# A31T21x register map
Vendor: ABOV Semiconductor Co., Ltd.; Series: A31T21x; File version: 1.0
CPU: CM0PLUS r0p1, little endian, no MPU, no FPU, VTOR, 2 interrupt priority bits
Registers are 32-bit, read-write, reset 0x0 unless marked. A register's access mark holds for its fields unless they carry their own. Offsets are from the block's base; [hi:lo] are bit positions; {n}, {i} and the like mark numbered series.

## SCU — System Control Unit
Base 0x40000000
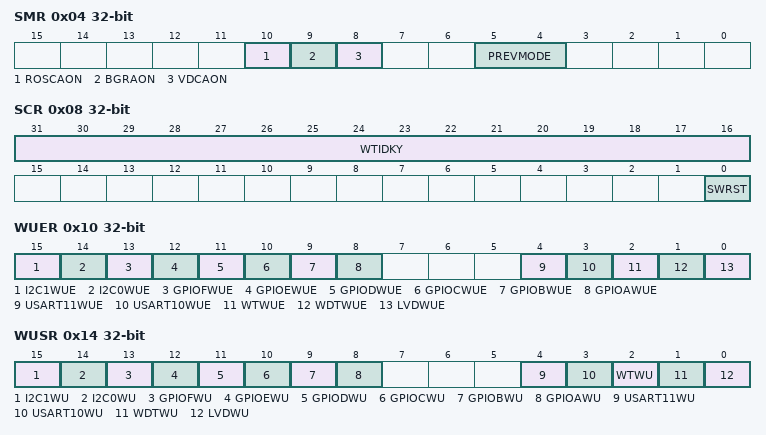
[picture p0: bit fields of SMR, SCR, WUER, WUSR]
0x04 SMR — System Mode Register
  [10] ROSCAON — ROSC Always on select bit in power down mode 0: ROSC is automatically off entering power down mode 1: ROSC isn't automatically off entering power down mode
  [9] BGRAON — BGR Always on select bit in power down mode 0: BGR is automatically off entering power down mode 1: BGR isn't automatically off entering power down mode
  [8] VDCAON — VDC Always on select bit in power down mode
  [5:4] PREVMODE ro — Previous operating mode before current reset event
0x08 SCR — System Control Register
  [31:16] WTIDKY wo — On writes, write 0x9EB3 to these bits, otherwise the write is ignored.
  [0] SWRST — Internal soft reset activation bit (check RSER[4] for reset)
0x10 WUER — Wake up source enable register
  [15] I2C1WUE — Enable wakeup source of I2C1 event
  [14] I2C0WUE — Enable wakeup source of I2C0 event
  [13] GPIOFWUE — Enable wakeup source of GPIOF port pin change event
  [12] GPIOEWUE — Enable wakeup source of GPIOE port pin change event
  [11] GPIODWUE — Enable wakeup source of GPIOD port pin change event
  [10] GPIOCWUE — Enable wakeup source of GPIOC port pin change event
  [9] GPIOBWUE — Enable wakeup source of GPIOB port pin change event
  [8] GPIOAWUE — Enable wakeup source of GPIOA port pin change event
  [4] USART11WUE — Enable wakeup source of USART11 event
  [3] USART10WUE — Enable wakeup source of USART10 event
  [2] WTWUE — Enable wakeup source of watch timer event
  [1] WDTWUE — Enable wakeup source of watchdog timer event
  [0] LVDWUE — Enable wakeup source of LVD event
0x14 WUSR ro — Wake up source status register
  [15] I2C1WU — Status of wakeup source of I2C1 event
  [14] I2C0WU — Status of wakeup source of I2C0 event
  [13] GPIOFWU — Status of wakeup source of GPIOF port pin change event
  [12] GPIOEWU — Status of wakeup source of GPIOE port pin change event
  [11] GPIODWU — Status of wakeup source of GPIOD port pin change event
  [10] GPIOCWU — Status of wakeup source of GPIOC port pin change event
  [9] GPIOBWU — Status of wakeup source of GPIOB port pin change event
  [8] GPIOAWU — Status of wakeup source of GPIOA port pin change event
  [4] USART11WU — Status of wakeup source of USART11 event
  [3] USART10WU — Status of wakeup source of USART10 event
  [2] WTWU — Status of wakeup source of watch timer event
  [1] WDTWU — Status of wakeup source of watchdog timer event
  [0] LVDWU — Status of wakeup source of LVD event
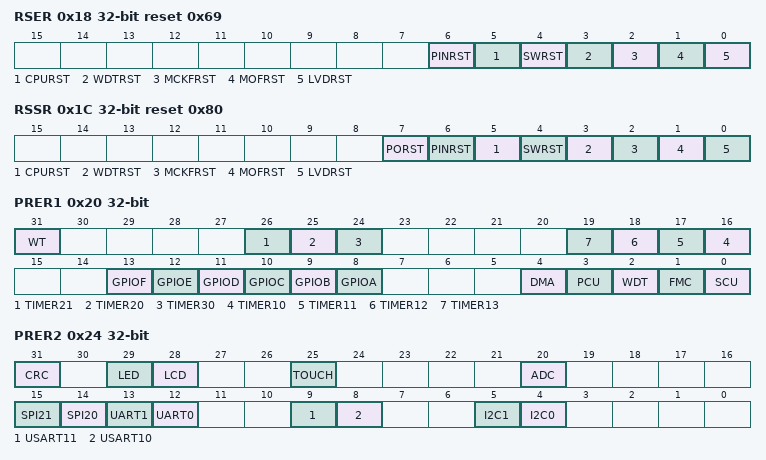
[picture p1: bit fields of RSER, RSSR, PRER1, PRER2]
0x18 RSER reset 0x69 — Reset source enable register
  [6] PINRST — External pin reset enable bit
  [5] CPURST — CPU request reset enable bit
  [4] SWRST — Software reset enable bit
  [3] WDTRST — Watchdog Timer reset enable bit
  [2] MCKFRST — MCLK Clock fail reset enable bit
  [1] MOFRST — MOSC Clock fail reset enable bit
  [0] LVDRST — LVD reset enable bit
0x1C RSSR reset 0x80 — Reset source status register
  [7] PORST — Power on reset status bit
  [6] PINRST — External pin reset status bit
  [5] CPURST — CPU request reset status bit
  [4] SWRST — Software reset status bit
  [3] WDTRST — Watchdog Timer reset status bit
  [2] MCKFRST — MCLK Clock fail reset status bit
  [1] MOFRST — MOSC Clock fail reset status bit
  [0] LVDRST — LVD reset status bit
0x20 PRER1 — Peripheral reset enable register 1
  [31] WT — WT reset mask
  [26] TIMER21 — TIMER21 reset mask
  [25] TIMER20 — TIMER20 reset mask
  [24] TIMER30 — TIMER30 reset mask
  [n+6] TIMER{n} (n=10..13) — TIMER{n} reset mask
  [13] GPIOF — GPIOF reset mask
  [12] GPIOE — GPIOE reset mask
  [11] GPIOD — GPIOD reset mask
  [10] GPIOC — GPIOC reset mask
  [9] GPIOB — GPIOB reset mask
  [8] GPIOA — GPIOA reset mask
  [4] DMA — DMA reset mask
  [3] PCU — PCU reset mask
  [2] WDT — WDT reset mask
  [1] FMC — FMC reset mask
  [0] SCU — SCU reset mask
0x24 PRER2 — Peripheral reset enable register 2
  [31] CRC — CRC reset mask
  [29] LED — LED reset mask
  [28] LCD — LCD reset mask
  [25] TOUCH — TOUCH reset mask
  [20] ADC — ADC reset mask
  [15] SPI21 — SPI21 reset mask
  [14] SPI20 — SPI20 reset mask
  [13] UART1 — UART1 reset mask
  [12] UART0 — UART0 reset mask
  [9] USART11 — USART11 reset mask
  [8] USART10 — USART10 reset mask
  [5] I2C1 — I2C1 reset mask
  [4] I2C0 — I2C0 reset mask
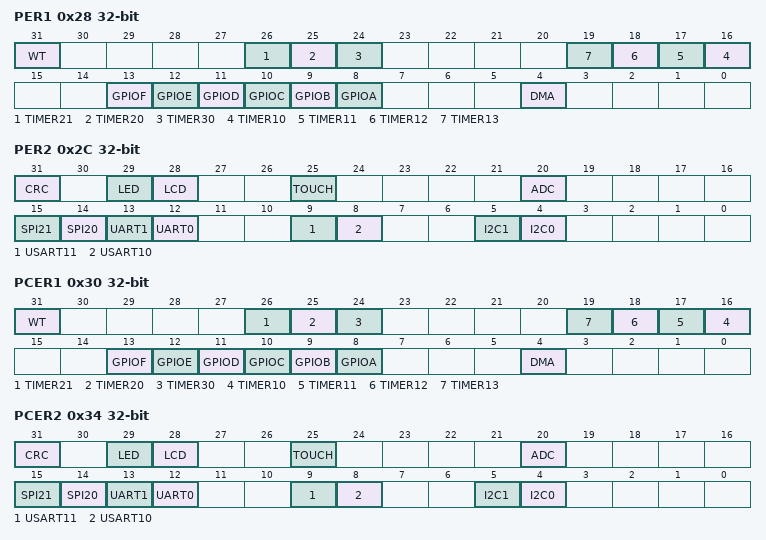
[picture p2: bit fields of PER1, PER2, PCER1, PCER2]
0x28 PER1 — Peripheral enable register 1
  [31] WT — WT function enable
  [26] TIMER21 — TIMER21 function enable
  [25] TIMER20 — TIMER20 function enable
  [24] TIMER30 — TIMER30 function enable
  [n+6] TIMER{n} (n=10..13) — TIMER{n} function enable
  [13] GPIOF — GPIOF function enable
  [12] GPIOE — GPIOE function enable
  [11] GPIOD — GPIOD function enable
  [10] GPIOC — GPIOC function enable
  [9] GPIOB — GPIOB function enable
  [8] GPIOA — GPIOA function enable
  [4] DMA — DMA function enable
0x2C PER2 — Peripheral enable register 2
  [31] CRC — CRC function enable
  [29] LED — LED function enable
  [28] LCD — LCD function enable
  [25] TOUCH — TOUCH function enable
  [20] ADC — ADC function enable
  [15] SPI21 — SPI21 function enable
  [14] SPI20 — SPI20 function enable
  [13] UART1 — UART1 function enable
  [12] UART0 — UART0 function enable
  [9] USART11 — USART11 function enable
  [8] USART10 — USART10 function enable
  [5] I2C1 — I2C1 function enable
  [4] I2C0 — I2C0 function enable
0x30 PCER1 — Peripheral clock enable register 1
  [31] WT — WT clock enable
  [26] TIMER21 — TIMER21 clock enable
  [25] TIMER20 — TIMER20 clock enable
  [24] TIMER30 — TIMER30 clock enable
  [n+6] TIMER{n} (n=10..13) — TIMER{n} clock enable
  [13] GPIOF — GPIOF clock enable
  [12] GPIOE — GPIOE clock enable
  [11] GPIOD — GPIOD clock enable
  [10] GPIOC — GPIOC clock enable
  [9] GPIOB — GPIOB clock enable
  [8] GPIOA — GPIOA clock enable
  [4] DMA — DMA clock enable
0x34 PCER2 — Peripheral clock enable register 2
  [31] CRC — CRC clock enable
  [29] LED — LED clock enable
  [28] LCD — LCD clock enable
  [25] TOUCH — TOUCH clock enable
  [20] ADC — ADC clock enable
  [15] SPI21 — SPI21 clock enable
  [14] SPI20 — SPI20 clock enable
  [13] UART1 — UART1 clock enable
  [12] UART0 — UART0 clock enable
  [9] USART11 — USART11 clock enable
  [8] USART10 — USART10 clock enable
  [5] I2C1 — I2C1 clock enable
  [4] I2C0 — I2C0 clock enable
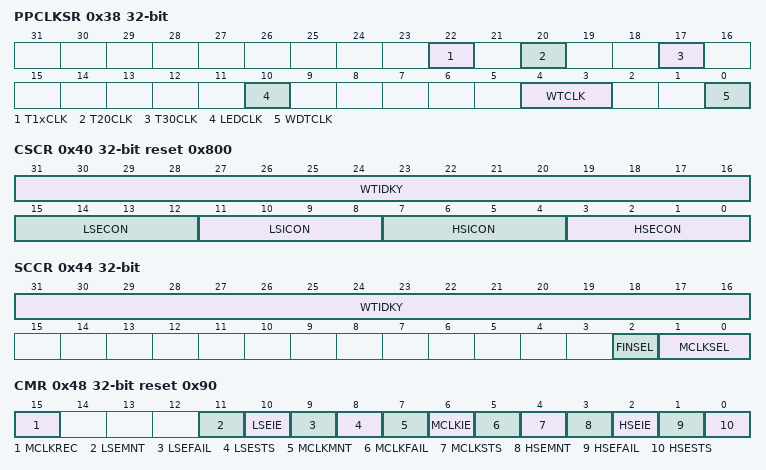
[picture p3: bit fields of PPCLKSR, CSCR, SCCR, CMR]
0x38 PPCLKSR — Peripheral clock selection register
  [22] T1xCLK — Timer 1x Clock Selection bit
  [20] T20CLK — Timer 20 Clock Selection bit
  [17] T30CLK — Timer 30 Clock Selection bit
  [10] LEDCLK — LED Clock Selection bit
  [4:3] WTCLK — Watch Timer Clock Selection bit Note) These bits should be changed during the WTEN bit of watch timer control register (WTCR) is "0b"
  [0] WDTCLK — Watch-dog Timer Clock Selection bit
0x40 CSCR reset 0x800 — Clock Source Control register
  [31:16] WTIDKY wo — On writes, write 0xA507 to these bits, otherwise the write is ignored.
  [15:12] LSECON — External crystal sub oscillator control
  [11:8] LSICON — Low speed internal oscillator control
  [7:4] HSICON — High speed internal oscillator control
  [3:0] HSECON — External crystal main oscillator control
0x44 SCCR — System Clock Control register
  [31:16] WTIDKY wo — On writes, write 0x570A to these bits, otherwise the write is ignored.
  [2] FINSEL — PLL input source FIN select register
  [1:0] MCLKSEL — System clock select register
0x48 CMR reset 0x90 — Clock Monitoring register
  [15] MCLKREC — MCLK fail auto recovery
  [11] LSEMNT — External sub oscillator monitoring enable
  [10] LSEIE — External sub oscillator fail interrupt enable
  [9] LSEFAIL — External sub oscillator fail interrupt
  [8] LSESTS — External sub oscillator status
  [7] MCLKMNT — MCLK monitoring enable
  [6] MCLKIE — MCLK fail interrupt enable
  [5] MCLKFAIL — MCLK fail interrupt
  [4] MCLKSTS — MCLK clock status
  [3] HSEMNT — External main oscillator monitoring enable
  [2] HSEIE — External main oscillator fail interrupt enable
  [1] HSEFAIL — External main oscillator fail interrupt
  [0] HSESTS — External main oscillator status
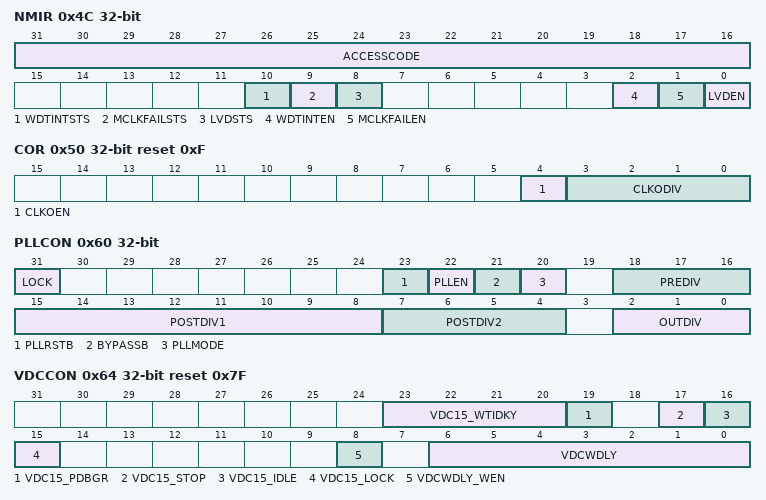
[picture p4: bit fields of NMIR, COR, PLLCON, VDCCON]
0x4C NMIR — NMI control register
  [31:16] ACCESSCODE wo — This field enables writing access to this register. Writing 0xA32C is to enable writing.
  [10] WDTINTSTS ro — WDT Interrupt condition status bit This bit can't invoke NMI interrupt without enable bit
  [9] MCLKFAILSTS ro — MCLK Fail condition status bit This bit can't invoke NMI interrupt without enable bit
  [8] LVDSTS ro — LVD condition status bit This bit can't invoke NMI interrupt without enable bit
  [2] WDTINTEN — WDT Interrupt condition enable for NMI interrupt
  [1] MCLKFAILEN — MCLK Fail condition enable for NMI interrupt
  [0] LVDEN — LVD Fail condition enable for NMI interrupt
0x50 COR reset 0xF — Clock Output Control register
  [4] CLKOEN — Clock output enable
  [3:0] CLKODIV — Clock output divider value CLKO=MCLK (CLKODIV=0) CLKO=MCLK/2(CLKODIV+1) (CLKODIV > 0)
0x60 PLLCON — PLL Control register
  [31] LOCK ro — LOCK status
  [23] PLLRSTB — PLL reset
  [22] PLLEN — PLL enable
  [21] BYPASSB — FIN bypass
  [20] PLLMODE — PLL VCO mode
  [18:16] PREDIV — FIN predivider FIN divided by (PREDIV + 1), (FIN/1 ~ FIN/8)
  [15:8] POSTDIV1 — Feedback control 1 (N1) N1 = POSTDIV1 + 1
  [7:4] POSTDIV2 — Feedback control 1 (N2) N2 = POSTDIV2 + 1
  [2:0] OUTDIV — output divider control (P) P = OUTDIV + 1
0x64 VDCCON reset 0x7F — VDC Control register
  [23:20] VDC15_WTIDKY wo — VDC15 Write Identification Key On writes, write 0x5 to these bits, otherwise the write is ignored.
  [19] VDC15_PDBGR — VDC15 1.2V BGR / 1.0V Buffer Power Down Signal *In BGR on off, VDCLOCK_I should be 0
  [17] VDC15_STOP — VDC15 STOP Mode Control Signal
  [16] VDC15_IDLE — VDC15 STOP1 Mode Control Signal
  [15] VDC15_LOCK — VDC15 VDCLOCK Control Signal for *BGR Stabilization *In BGR off on Sequence, VDCLOCK_I should be 0 during 120usec
  [8] VDCWDLY_WEN wo — VDCWDLY value write enable. VDCWDLY value can be written with writing '1' to VDCWDLY_WEN bit simultaneously.
  [6:0] VDCWDLY — VDC warm-up delay count value. When SCU is waked up from powerdown mode, the warm-up delay is inserted for VDC output being stabilized. The amount of delay can be defined with this register value 7F : 4msec
0x68 TIRCCON — On chip Internal IRC for Touch control register
  [0] TIRCON — Touch IRC Control signal
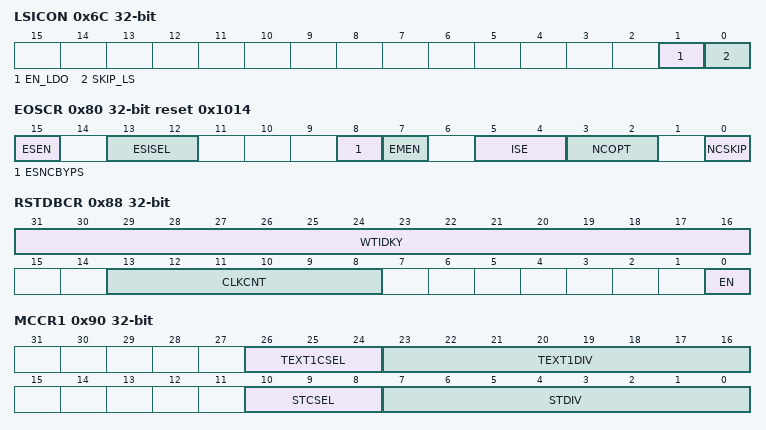
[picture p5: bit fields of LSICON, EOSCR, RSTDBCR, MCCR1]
0x6C LSICON — LSI Control Register
  [1] EN_LDO — Internal LDO On/Off
  [0] SKIP_LS — Internal Level Shifter control signal
0x80 EOSCR reset 0x1014 — External Oscillator control register
  [15] ESEN wo — Write enable for External SOSC
  [13:12] ESISEL — Internal Level Shifter control signal
  [8] ESNCBYPS — Noise Cancel Bypass enable for External SOSC
  [7] EMEN wo — Write enable for External MOSC
  [5:4] ISE — Select current for External MOSC
  [3:2] NCOPT — Noise Cancel delay Option for External MOSC
  [0] NCSKIP — Noise Cancel Bypass enable for External SOSC
0x84 EMODR — External mode pin read register
  [0] BOOT ro — BOOT pin level
0x88 RSTDBCR — Pin Reset Debounce Control Register
  [31:16] WTIDKY wo — Write Identification Key
  [13:8] CLKCNT — Noise Cancel delay Option for External HSE
  [0] EN — Pin reset debounce enable bit
0x90 MCCR1 — Miscellaneous Clock Control Register 1
  [26:24] TEXT1CSEL — TIMER1n EXT Clock source select bit
  [23:16] TEXT1DIV — TIMER1n EXT Clock N divider To change the value, set 0x0 first without changing TEXT1CSEL
  [10:8] STCSEL — systick clock source sel
  [7:0] STDIV — SYSTICK Clock N divider To change the value, set 0x0 first without changing STCSEL
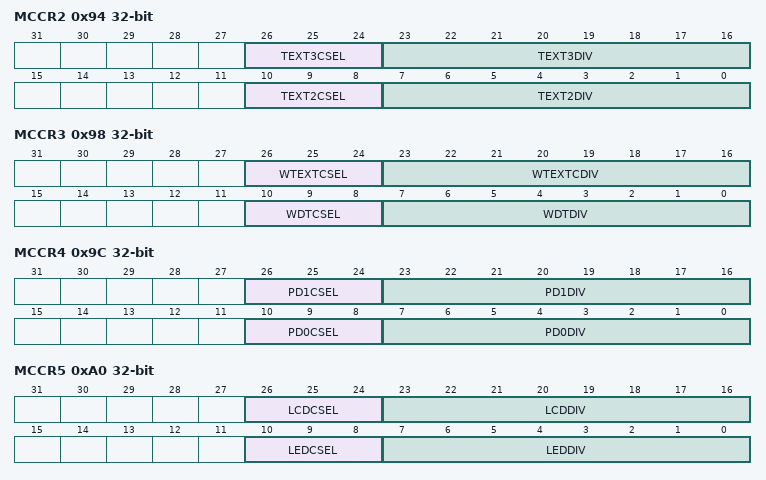
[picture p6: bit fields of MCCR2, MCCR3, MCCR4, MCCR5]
0x94 MCCR2 — Miscellaneous Clock Control Register 2
  [26:24] TEXT3CSEL — TIMER 30 EXT Clock source select bit
  [23:16] TEXT3DIV — TIMER 30 EXT Clock N divider To change the value, set 0x0 first without changing TEXT3DIV
  [10:8] TEXT2CSEL
  [7:0] TEXT2DIV — TIMER 20 EXT Clock N divider To change the value, set 0x0 first without changing TEXT2CSEL
0x98 MCCR3 — Miscellaneous Clock Control Register 3
  [26:24] WTEXTCSEL
  [23:16] WTEXTCDIV — WT External Clock N divider To change the value, set 0x0 first without changing WTEXTCSEL
  [10:8] WDTCSEL — WDT clock sel
  [7:0] WDTDIV — WDT Clock N divider To change the value, set 0x0 first without changing WDTCSEL
0x9C MCCR4 — Miscellaneous Clock Control Register 4
  [26:24] PD1CSEL — Debounce Clock for PORT source select bit (PD,PE,PF)
  [23:16] PD1DIV — PORT Debounce Clock N divider (PD,PE,PF) To change the value, set 0x0 first without changing PD1CSEL
  [10:8] PD0CSEL — Debounce Clock for PORT source select bit (PA,PB,PC)
  [7:0] PD0DIV — PORT Debounce Clock N divider (PA,PB,PC) To change the value, set 0x0 first without changing PD0CSEL
0xA0 MCCR5 — Miscellaneous Clock Control Register 5
  [26:24] LCDCSEL — LCD Clock source select bit
  [23:16] LCDDIV — LCD Clock N divider
  [10:8] LEDCSEL — LED Clock source select bit
  [7:0] LEDDIV — LED Clock N divider To change the value, set 0x0 first without changing LEDCSEL
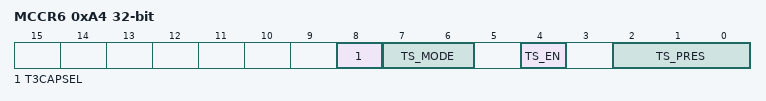
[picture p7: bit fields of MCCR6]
0xA4 MCCR6 — Miscellaneous Clock Control Register 6
  [8] T3CAPSEL — Timer30 Capture Enable bit
  [7:6] TS_MODE — Temp-sensor mode selection
  [4] TS_EN — Temperature Sensor enable
  [2:0] TS_PRES — Temperature Sensor period

## Notices in the file
Copyright (C) 2012-2014 ARM Limited. All rights reserved.
Purpose: System Viewer Description (SVD) Example (Schema Version 1.1)
This is a description of a none-existent and incomplete device
for demonstration purposes only.
Redistribution and use in source and binary forms, with or without
modification, are permitted provided that the following conditions are met:
- Redistributions of source code must retain the above copyright
notice, this list of conditions and the following disclaimer.
- Redistributions in binary form must reproduce the above copyright
notice, this list of conditions and the following disclaimer in the
documentation and/or other materials provided with the distribution.
- Neither the name of ARM nor the names of its contributors may be used
to endorse or promote products derived from this software without
specific prior written permission.
THIS SOFTWARE IS PROVIDED BY THE COPYRIGHT HOLDERS AND CONTRIBUTORS "AS IS"
AND ANY EXPRESS OR IMPLIED WARRANTIES, INCLUDING, BUT NOT LIMITED TO, THE
IMPLIED WARRANTIES OF MERCHANTABILITY AND FITNESS FOR A PARTICULAR PURPOSE
ARE DISCLAIMED. IN NO EVENT SHALL COPYRIGHT HOLDERS AND CONTRIBUTORS BE
LIABLE FOR ANY DIRECT, INDIRECT, INCIDENTAL, SPECIAL, EXEMPLARY, OR
CONSEQUENTIAL DAMAGES (INCLUDING, BUT NOT LIMITED TO, PROCUREMENT OF
SUBSTITUTE GOODS OR SERVICES; LOSS OF USE, DATA, OR PROFITS; OR BUSINESS
INTERRUPTION) HOWEVER CAUSED AND ON ANY THEORY OF LIABILITY, WHETHER IN
CONTRACT, STRICT LIABILITY, OR TORT (INCLUDING NEGLIGENCE OR OTHERWISE)
ARISING IN ANY WAY OUT OF THE USE OF THIS SOFTWARE, EVEN IF ADVISED OF THE
POSSIBILITY OF SUCH DAMAGE.
